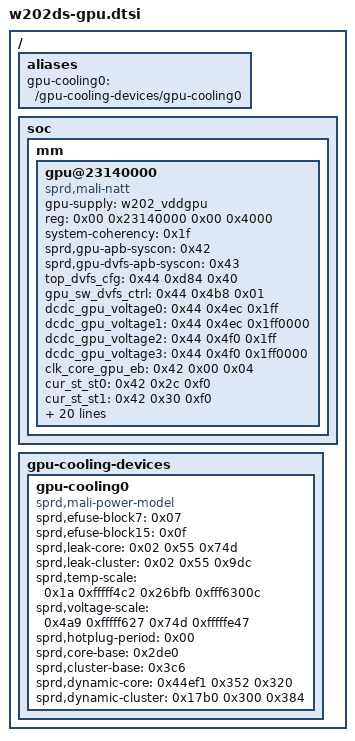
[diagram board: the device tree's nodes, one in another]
// W202DS Server hardware layout; split from the validated imported tree.
/ {
	aliases {
		gpu-cooling0 = "/gpu-cooling-devices/gpu-cooling0";
	};
	soc {
		mm {
			gpu@23140000 {
				gpu-supply = <&w202_vddgpu>;
				compatible = "sprd,mali-natt";
				reg = <0x00 0x23140000 0x00 0x4000>;
				system-coherency = <0x1f>;
				sprd,gpu-apb-syscon = <0x42>;
				sprd,gpu-dvfs-apb-syscon = <0x43>;
				top_dvfs_cfg = <0x44 0xd84 0x40>;
				gpu_sw_dvfs_ctrl = <0x44 0x4b8 0x01>;
				dcdc_gpu_voltage0 = <0x44 0x4ec 0x1ff>;
				dcdc_gpu_voltage1 = <0x44 0x4ec 0x1ff0000>;
				dcdc_gpu_voltage2 = <0x44 0x4f0 0x1ff>;
				dcdc_gpu_voltage3 = <0x44 0x4f0 0x1ff0000>;
				clk_core_gpu_eb = <0x42 0x00 0x04>;
				cur_st_st0 = <0x42 0x2c 0xf0>;
				cur_st_st1 = <0x42 0x30 0xf0>;
				cur_st_st2 = <0x42 0x34 0xf0>;
				cur_st_st3 = <0x42 0x38 0xf0>;
				top_force_shutdown = <0x04 0x2c4 0x2000000>;
				gpu_top_state = <0x04 0x500 0x1f0000>;
				gpu_core0_state = <0x04 0x500 0x1f000000>;
				gpu_core1_state = <0x04 0x504 0x1f>;
				gpu_core2_state = <0x04 0x504 0x1f00>;
				gpu_core3_state = <0x04 0x504 0x1f0000>;
				gpll_cfg_frc_off = <0x04 0xa20 0x02>;
				gpll_cfg_frc_on = <0x04 0xa20 0x01>;
				resets = <0x28 0x03>;
				reset-names = "gpu_soft_rst";
				interrupts = <0x00 0x92 0x04 0x00 0x92 0x04 0x00 0x92 0x04>;
				interrupt-names = "JOB", "MMU", "GPU";
				nvmem-cells = <0x45>;
				nvmem-cell-names = "gpu_bin";
				operating-points = <0x6590 0x86470 0x12c00 0x86470 0x25800 0x86470 0x5dc00 0x927c0 0x7d000 0x9eb10 0xa6040 0xaae60 0xcf850 0xb71b0>;
				sprd,dvfs-default = <0x00>;
				clocks = <0x11 0x08 0x16 0x02 0x0b 0x07 0x0b 0x0a 0x0b 0x0e 0x0b 0x0f 0x46 0x00 0x46 0x02>;
				phandle = <0x165>;
			};
		};
	};
	gpu-cooling-devices {
		gpu-cooling0 {
			compatible = "sprd,mali-power-model";
			#cooling-cells = <0x02>;
			sprd,efuse-block7 = <0x07>;
			sprd,efuse-block15 = <0x0f>;
			sprd,leak-core = <0x02 0x55 0x74d>;
			sprd,leak-cluster = <0x02 0x55 0x9dc>;
			sprd,temp-scale = <0x1a 0xfffff4c2 0x26bfb 0xfff6300c>;
			sprd,voltage-scale = <0x4a9 0xfffff627 0x74d 0xfffffe47>;
			sprd,hotplug-period = <0x00>;
			sprd,core-base = <0x2de0>;
			sprd,cluster-base = <0x3c6>;
			sprd,dynamic-core = <0x44ef1 0x352 0x320>;
			sprd,dynamic-cluster = <0x17b0 0x300 0x384>;
			phandle = <0x11d>;
		};
	};
	__symbols__ {
		gpu = "/soc/mm/gpu@23140000";
		gpu_cooling0 = "/gpu-cooling-devices/gpu-cooling0";
	};
};
